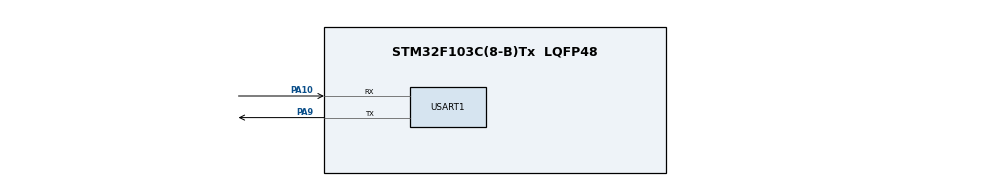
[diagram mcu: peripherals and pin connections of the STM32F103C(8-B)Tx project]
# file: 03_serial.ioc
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Mcu.Family=STM32F1
Mcu.Name=STM32F103C(8-B)Tx
Mcu.Package=LQFP48
NVIC.PriorityGroup=NVIC_PRIORITYGROUP_4
NVIC.USART1_IRQn=true\:0\:0\:false\:false\:true\:true
PA10.Mode=Asynchronous
PA10.Signal=USART1_RX
PA13.Mode=Serial_Wire
PA13.Signal=SYS_JTMS-SWDIO
PA14.Mode=Serial_Wire
PA14.Signal=SYS_JTCK-SWCLK
PA9.Mode=Asynchronous
PA9.Signal=USART1_TX
ProjectManager.HeapSize=0x200
ProjectManager.StackSize=0x400
ProjectManager.TargetToolchain=MDK-ARM V5
RCC.APB1Freq_Value=8000000
RCC.APB2Freq_Value=8000000
USART1.VirtualMode=VM_ASYNC
board=custom

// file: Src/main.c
/* USER CODE BEGIN Header */
/**
  ******************************************************************************
  * @file           : main.c
  * @brief          : Main program body
  ******************************************************************************
  ** This notice applies to any and all portions of this file
  * that are not between comment pairs USER CODE BEGIN and
  * USER CODE END. Other portions of this file, whether
  * inserted by the user or by software development tools
  * are owned by their respective copyright owners.
  *
  * COPYRIGHT(c) 2019 STMicroelectronics
  *
  * Redistribution and use in source and binary forms, with or without modification,
  * are permitted provided that the following conditions are met:
  *   1. Redistributions of source code must retain the above copyright notice,
  *      this list of conditions and the following disclaimer.
  *   2. Redistributions in binary form must reproduce the above copyright notice,
  *      this list of conditions and the following disclaimer in the documentation
  *      and/or other materials provided with the distribution.
  *   3. Neither the name of STMicroelectronics nor the names of its contributors
  *      may be used to endorse or promote products derived from this software
  *      without specific prior written permission.
  *
  * THIS SOFTWARE IS PROVIDED BY THE COPYRIGHT HOLDERS AND CONTRIBUTORS "AS IS"
  * AND ANY EXPRESS OR IMPLIED WARRANTIES, INCLUDING, BUT NOT LIMITED TO, THE
  * IMPLIED WARRANTIES OF MERCHANTABILITY AND FITNESS FOR A PARTICULAR PURPOSE ARE
  * DISCLAIMED. IN NO EVENT SHALL THE COPYRIGHT HOLDER OR CONTRIBUTORS BE LIABLE
  * FOR ANY DIRECT, INDIRECT, INCIDENTAL, SPECIAL, EXEMPLARY, OR CONSEQUENTIAL
  * DAMAGES (INCLUDING, BUT NOT LIMITED TO, PROCUREMENT OF SUBSTITUTE GOODS OR
  * SERVICES; LOSS OF USE, DATA, OR PROFITS; OR BUSINESS INTERRUPTION) HOWEVER
  * CAUSED AND ON ANY THEORY OF LIABILITY, WHETHER IN CONTRACT, STRICT LIABILITY,
  * OR TORT (INCLUDING NEGLIGENCE OR OTHERWISE) ARISING IN ANY WAY OUT OF THE USE
  * OF THIS SOFTWARE, EVEN IF ADVISED OF THE POSSIBILITY OF SUCH DAMAGE.
  *
  ******************************************************************************
  */
/* USER CODE END Header */

#include "main.h"
#include "string.h"

UART_HandleTypeDef huart1;

void SystemClock_Config(void);
static void MX_GPIO_Init(void);
static void MX_USART1_UART_Init(void);

	char tx[]="Hello From STM32\n";

	char rx_buffer[100];
	uint8_t rx_index;
	unsigned char rx_data[2];

int main(void)
{

  /* MCU Configuration--------------------------------------------------------*/

  /* Reset of all peripherals, Initializes the Flash interface and the Systick. */
  HAL_Init();

  /* Configure the system clock */
  SystemClock_Config();

  /* Initialize all configured peripherals */
  MX_GPIO_Init();
  MX_USART1_UART_Init();
  /* USER CODE BEGIN 2 */
	HAL_UART_Receive_IT(&huart1,rx_data,1);
  /* USER CODE END 2 */

  /* Infinite loop */
  while (1)
  {
		HAL_UART_Transmit(&huart1, (uint8_t *)tx, strlen(tx), 100);
		HAL_Delay(1000);
  }
}

void HAL_UART_RxCpltCallback(UART_HandleTypeDef *huart){
	uint8_t i;
	if(huart->Instance == USART1){
		if(rx_index==0){
			  for(i=0;i<100;i++){
					rx_buffer[i]=0;
				}
		}
		if(rx_data[0] != 13){  // ascii code key enter (\n)
			rx_buffer[rx_index++]=rx_data[0];
		}else{
			rx_index=0;
			if(!strcmp(rx_buffer,"led on")){
				char tx1[]="set led on\n";
				HAL_UART_Transmit(&huart1, (uint8_t *)tx1, strlen(tx1), 100);
			}
			if(!strcmp(rx_buffer,"led off")){
				char tx2[]="set led off\n";
				HAL_UART_Transmit(&huart1, (uint8_t *)tx2, strlen(tx2), 100);
			}
		}
		HAL_UART_Receive_IT(&huart1,rx_data,1);
	}
}

/*
  * @brief System Clock Configuration
  * @retval None
  */
void SystemClock_Config(void)
{
  RCC_OscInitTypeDef RCC_OscInitStruct = {0};
  RCC_ClkInitTypeDef RCC_ClkInitStruct = {0};

  /**Initializes the CPU, AHB and APB busses clocks
  */
  RCC_OscInitStruct.OscillatorType = RCC_OSCILLATORTYPE_HSI;
  RCC_OscInitStruct.HSIState = RCC_HSI_ON;
  RCC_OscInitStruct.HSICalibrationValue = RCC_HSICALIBRATION_DEFAULT;
  RCC_OscInitStruct.PLL.PLLState = RCC_PLL_NONE;
  if (HAL_RCC_OscConfig(&RCC_OscInitStruct) != HAL_OK)
  {
    Error_Handler();
  }
  /**Initializes the CPU, AHB and APB busses clocks
  */
  RCC_ClkInitStruct.ClockType = RCC_CLOCKTYPE_HCLK|RCC_CLOCKTYPE_SYSCLK
                              |RCC_CLOCKTYPE_PCLK1|RCC_CLOCKTYPE_PCLK2;
  RCC_ClkInitStruct.SYSCLKSource = RCC_SYSCLKSOURCE_HSI;
  RCC_ClkInitStruct.AHBCLKDivider = RCC_SYSCLK_DIV1;
  RCC_ClkInitStruct.APB1CLKDivider = RCC_HCLK_DIV1;
  RCC_ClkInitStruct.APB2CLKDivider = RCC_HCLK_DIV1;

  if (HAL_RCC_ClockConfig(&RCC_ClkInitStruct, FLASH_LATENCY_0) != HAL_OK)
  {
    Error_Handler();
  }
}

static void MX_USART1_UART_Init(void)
{

  huart1.Instance = USART1;
  huart1.Init.BaudRate = 115200;
  huart1.Init.WordLength = UART_WORDLENGTH_8B;
  huart1.Init.StopBits = UART_STOPBITS_1;
  huart1.Init.Parity = UART_PARITY_NONE;
  huart1.Init.Mode = UART_MODE_TX_RX;
  huart1.Init.HwFlowCtl = UART_HWCONTROL_NONE;
  huart1.Init.OverSampling = UART_OVERSAMPLING_16;
  if (HAL_UART_Init(&huart1) != HAL_OK)
  {
    Error_Handler();
  }

}

static void MX_GPIO_Init(void)
{

  /* GPIO Ports Clock Enable */
  __HAL_RCC_GPIOA_CLK_ENABLE();

}

void Error_Handler(void)
{
}

/************************ (C) COPYRIGHT STMicroelectronics *****END OF FILE****/
